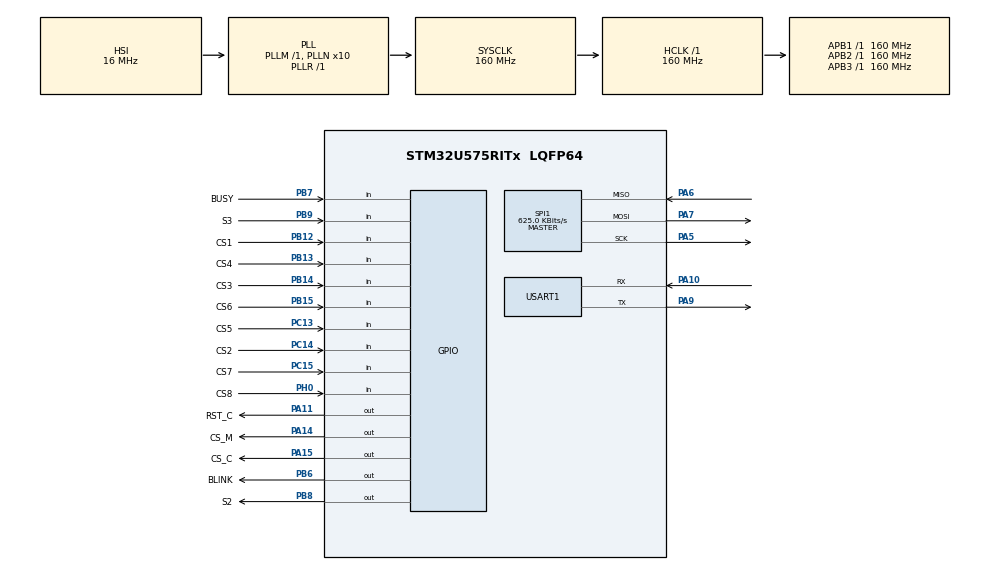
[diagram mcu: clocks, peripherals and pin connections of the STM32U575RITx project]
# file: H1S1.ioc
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CORTEX_M33_NS.userName=CORTEX_M33
Mcu.Family=STM32U5
Mcu.Name=STM32U575RITx
Mcu.Package=LQFP64
NVIC.PriorityGroup=NVIC_PRIORITYGROUP_4
NVIC.USART1_IRQn=true\:0\:0\:false\:false\:true\:true\:true\:true
PA10.Mode=Asynchronous
PA10.Signal=USART1_RX
PA11.GPIO_Label=RST_C
PA11.PinState=GPIO_PIN_RESET
PA11.Signal=GPIO_Output
PA14\ (JTCK/SWCLK).GPIO_Label=CS_M
PA14\ (JTCK/SWCLK).PinState=GPIO_PIN_SET
PA14\ (JTCK/SWCLK).Signal=GPIO_Output
PA15\ (JTDI).GPIO_Label=CS_C
PA15\ (JTDI).PinState=GPIO_PIN_SET
PA15\ (JTDI).Signal=GPIO_Output
PA5.Mode=Full_Duplex_Master
PA5.Signal=SPI1_SCK
PA6.Mode=Full_Duplex_Master
PA6.Signal=SPI1_MISO
PA7.Mode=Full_Duplex_Master
PA7.Signal=SPI1_MOSI
PA9.GPIO_ModeDefaultPP=GPIO_MODE_AF_OD
PA9.GPIO_PuPd=GPIO_PULLUP
PA9.Mode=Asynchronous
PA9.Signal=USART1_TX
PB12.GPIO_Label=CS1
PB12.Signal=GPIO_Input
PB13.GPIO_Label=CS4
PB13.Signal=GPIO_Input
PB14.GPIO_Label=CS3
PB14.Signal=GPIO_Input
PB15.GPIO_Label=CS6
PB15.Signal=GPIO_Input
PB6.GPIO_Label=BLINK
PB6.PinState=GPIO_PIN_SET
PB6.Signal=GPIO_Output
PB7.GPIO_Label=BUSY
PB7.Signal=GPIO_Input
PB8.GPIO_Label=S2
PB8.Signal=GPIO_Output
PB9.GPIO_Label=S3
PB9.Signal=GPIO_Input
PC13.GPIO_Label=CS5
PC13.Signal=GPIO_Input
PC14-OSC32_IN\ (PC14).GPIO_Label=CS2
PC14-OSC32_IN\ (PC14).Signal=GPIO_Input
PC15-OSC32_OUT\ (PC15).GPIO_Label=CS7
PC15-OSC32_OUT\ (PC15).Signal=GPIO_Input
PH0-OSC_IN\ (PH0).GPIO_Label=CS8
PH0-OSC_IN\ (PH0).Signal=GPIO_Input
ProjectManager.HeapSize=0x200
ProjectManager.StackSize=0x400
ProjectManager.TargetToolchain=STM32CubeIDE
RCC.ADCFreq_Value=16000000
RCC.AHBFreq_Value=160000000
RCC.APB1Freq_Value=160000000
RCC.APB1TimFreq_Value=160000000
RCC.APB2Freq_Value=160000000
RCC.APB2TimFreq_Value=160000000
RCC.APB3Freq_Value=160000000
RCC.CortexFreq_Value=160000000
RCC.EPOD_VALUE=16000000
RCC.HCLKFreq_Value=160000000
RCC.HSE_VALUE=16000000
RCC.HSI48_VALUE=48000000
RCC.HSI_VALUE=16000000
RCC.LSE_VALUE=32768
RCC.LSIDIV_VALUE=32000
RCC.MSI_VALUE=4000000
RCC.PLL1R=1
RCC.PLLFRACN=0
RCC.PLLN=10
RCC.PLLSourceVirtual=RCC_PLLSOURCE_HSI
RCC.SYSCLKFreq_VALUE=160000000
RCC.SYSCLKSource=RCC_SYSCLKSOURCE_PLLCLK
RCC.USBFreq_Value=48000000
RCC.VCOOutputFreq_Value=160000000
SPI1.BaudRatePrescaler=SPI_BAUDRATEPRESCALER_256
SPI1.CLKPolarity=SPI_POLARITY_LOW
SPI1.CalculateBaudRate=625.0 KBits/s
SPI1.DataSize=SPI_DATASIZE_8BIT
SPI1.Direction=SPI_DIRECTION_2LINES
SPI1.Mode=SPI_MODE_MASTER
SPI1.VirtualType=VM_MASTER
USART1.VirtualMode-Asynchronous=VM_ASYNC
VP_LPBAMQUEUE_VS_QUEUE.Mode=QUEUEMODE
VP_LPBAM_VS_SIG1.Mode=SmartRun
VP_LPBAM_VS_SIG4.Mode=LPDMA1
VP_MEMORYMAP_VS_MEMORYMAP.Mode=CurAppReg
VP_PWR_VS_SECSignals.Mode=Security/Privilege
board=custom

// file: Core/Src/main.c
/* USER CODE BEGIN Header */
/**
 ******************************************************************************
 * @file           : main.c
 * @brief          : Main program body
 ******************************************************************************
 * @attention
 *
 * Copyright (c) 2024 STMicroelectronics.
 * All rights reserved.
 *
 * This software is licensed under terms that can be found in the LICENSE file
 * in the root directory of this software component.
 * If no LICENSE file comes with this software, it is provided AS-IS.
 *
 ******************************************************************************
 */
/* USER CODE END Header */
#include "main.h"

/* USER CODE BEGIN Includes */
#include "matrix.cs"
// All common MCU c functions
//#include "C:\dropbox\_mx\_0\fw\c\matrix.c"
//#include "C:\dropbox\_mx\_0\fw\c\dsp.c"
//#include "matrix.c"
/* USER CODE END Includes */

SPI_HandleTypeDef hspi1;

UART_HandleTypeDef huart1;

void SystemClock_Config(void);
static void MX_GPIO_Init(void);
static void MX_USART1_UART_Init(void);
static void MX_SPI1_Init(void);

/* USER CODE BEGIN 0 */
char UART1_Read(void) {
	char myChar[1] = " ";
	HAL_UART_Receive(&huart1, myChar, 1, 100);
	return myChar[0];
}
/*
 void DspTx( GPIO_TypeDef *dspPort, uint16_t dspCs, int dspAddressInt, int numBytes, unsigned char bytePtr[] )
 {
 int i = 0;
 char buffer[numBytes + 3];
 buffer[0] = 0;
 buffer[1] = dspAddressInt >>8; buffer[2] = dspAddressInt & 0xff;
 for (i = 0; i < numBytes; i++)
 {
 buffer[i + 3] = bytePtr[i];
 }
 // GPIO_TypeDef *GPIOx, uint16_t GPIO_Pin, GPIO_PinState PinState
 HAL_GPIO_WritePin(dspPort, dspCs, GPIO_PIN_RESET);
 // SPI_HandleTypeDef *hspi, const uint8_t *pData, uint16_t Size, uint32_t Timeout
 HAL_SPI_Transmit(&hspi1, buffer, numBytes + 3, 1000);
 HAL_GPIO_WritePin(dspPort, dspCs, GPIO_PIN_SET);
 }
 */
/* USER CODE END 0 */

int main(void)
{

  /* MCU Configuration--------------------------------------------------------*/

  /* Reset of all peripherals, Initializes the Flash interface and the Systick. */
  HAL_Init();

  /* Configure the system clock */
  SystemClock_Config();

  /* Initialize all configured peripherals */
  MX_GPIO_Init();
  MX_USART1_UART_Init();
  MX_SPI1_Init();
  /* USER CODE BEGIN 2 */
	//HAL_GPIO_WritePin(RST_D_GPIO_Port, RST_D_Pin, GPIO_PIN_RESET);
	//HAL_Delay(10);
	//HAL_GPIO_WritePin(RST_D_GPIO_Port, RST_D_Pin, GPIO_PIN_SET);
	__HAL_UART_ENABLE_IT(&huart1, UART_IT_RXNE);
  /* USER CODE END 2 */

  /* Infinite loop */
  /* USER CODE BEGIN WHILE */
	MainInit();
	while (1) {
    /* USER CODE END WHILE */

    /* USER CODE BEGIN 3 */
		MainLoop();
	}
  /* USER CODE END 3 */
}

void SystemClock_Config(void)
{
  RCC_OscInitTypeDef RCC_OscInitStruct = {0};
  RCC_ClkInitTypeDef RCC_ClkInitStruct = {0};

  /** Configure the main internal regulator output voltage
  */
  if (HAL_PWREx_ControlVoltageScaling(PWR_REGULATOR_VOLTAGE_SCALE1) != HAL_OK)
  {
    Error_Handler();
  }

  /** Initializes the CPU, AHB and APB buses clocks
  */
  RCC_OscInitStruct.OscillatorType = RCC_OSCILLATORTYPE_HSI;
  RCC_OscInitStruct.HSIState = RCC_HSI_ON;
  RCC_OscInitStruct.HSICalibrationValue = RCC_HSICALIBRATION_DEFAULT;
  RCC_OscInitStruct.PLL.PLLState = RCC_PLL_ON;
  RCC_OscInitStruct.PLL.PLLSource = RCC_PLLSOURCE_HSI;
  RCC_OscInitStruct.PLL.PLLMBOOST = RCC_PLLMBOOST_DIV1;
  RCC_OscInitStruct.PLL.PLLM = 1;
  RCC_OscInitStruct.PLL.PLLN = 10;
  RCC_OscInitStruct.PLL.PLLP = 2;
  RCC_OscInitStruct.PLL.PLLQ = 2;
  RCC_OscInitStruct.PLL.PLLR = 1;
  RCC_OscInitStruct.PLL.PLLRGE = RCC_PLLVCIRANGE_1;
  RCC_OscInitStruct.PLL.PLLFRACN = 0;
  if (HAL_RCC_OscConfig(&RCC_OscInitStruct) != HAL_OK)
  {
    Error_Handler();
  }

  /** Initializes the CPU, AHB and APB buses clocks
  */
  RCC_ClkInitStruct.ClockType = RCC_CLOCKTYPE_HCLK|RCC_CLOCKTYPE_SYSCLK
                              |RCC_CLOCKTYPE_PCLK1|RCC_CLOCKTYPE_PCLK2
                              |RCC_CLOCKTYPE_PCLK3;
  RCC_ClkInitStruct.SYSCLKSource = RCC_SYSCLKSOURCE_PLLCLK;
  RCC_ClkInitStruct.AHBCLKDivider = RCC_SYSCLK_DIV1;
  RCC_ClkInitStruct.APB1CLKDivider = RCC_HCLK_DIV1;
  RCC_ClkInitStruct.APB2CLKDivider = RCC_HCLK_DIV1;
  RCC_ClkInitStruct.APB3CLKDivider = RCC_HCLK_DIV1;

  if (HAL_RCC_ClockConfig(&RCC_ClkInitStruct, FLASH_LATENCY_4) != HAL_OK)
  {
    Error_Handler();
  }
}

static void MX_SPI1_Init(void)
{

  SPI_AutonomousModeConfTypeDef HAL_SPI_AutonomousMode_Cfg_Struct = {0};

  /* SPI1 parameter configuration*/
  hspi1.Instance = SPI1;
  hspi1.Init.Mode = SPI_MODE_MASTER;
  hspi1.Init.Direction = SPI_DIRECTION_2LINES;
  hspi1.Init.DataSize = SPI_DATASIZE_8BIT;
  hspi1.Init.CLKPolarity = SPI_POLARITY_LOW;
  hspi1.Init.CLKPhase = SPI_PHASE_1EDGE;
  hspi1.Init.NSS = SPI_NSS_SOFT;
  hspi1.Init.BaudRatePrescaler = SPI_BAUDRATEPRESCALER_256;
  hspi1.Init.FirstBit = SPI_FIRSTBIT_MSB;
  hspi1.Init.TIMode = SPI_TIMODE_DISABLE;
  hspi1.Init.CRCCalculation = SPI_CRCCALCULATION_DISABLE;
  hspi1.Init.CRCPolynomial = 0x7;
  hspi1.Init.NSSPMode = SPI_NSS_PULSE_ENABLE;
  hspi1.Init.NSSPolarity = SPI_NSS_POLARITY_LOW;
  hspi1.Init.FifoThreshold = SPI_FIFO_THRESHOLD_01DATA;
  hspi1.Init.MasterSSIdleness = SPI_MASTER_SS_IDLENESS_00CYCLE;
  hspi1.Init.MasterInterDataIdleness = SPI_MASTER_INTERDATA_IDLENESS_00CYCLE;
  hspi1.Init.MasterReceiverAutoSusp = SPI_MASTER_RX_AUTOSUSP_DISABLE;
  hspi1.Init.MasterKeepIOState = SPI_MASTER_KEEP_IO_STATE_DISABLE;
  hspi1.Init.IOSwap = SPI_IO_SWAP_DISABLE;
  hspi1.Init.ReadyMasterManagement = SPI_RDY_MASTER_MANAGEMENT_INTERNALLY;
  hspi1.Init.ReadyPolarity = SPI_RDY_POLARITY_HIGH;
  if (HAL_SPI_Init(&hspi1) != HAL_OK)
  {
    Error_Handler();
  }
  HAL_SPI_AutonomousMode_Cfg_Struct.TriggerState = SPI_AUTO_MODE_DISABLE;
  HAL_SPI_AutonomousMode_Cfg_Struct.TriggerSelection = SPI_GRP1_GPDMA_CH0_TCF_TRG;
  HAL_SPI_AutonomousMode_Cfg_Struct.TriggerPolarity = SPI_TRIG_POLARITY_RISING;
  if (HAL_SPIEx_SetConfigAutonomousMode(&hspi1, &HAL_SPI_AutonomousMode_Cfg_Struct) != HAL_OK)
  {
    Error_Handler();
  }

}

static void MX_USART1_UART_Init(void)
{

  huart1.Instance = USART1;
  huart1.Init.BaudRate = 115200;
  huart1.Init.WordLength = UART_WORDLENGTH_8B;
  huart1.Init.StopBits = UART_STOPBITS_1;
  huart1.Init.Parity = UART_PARITY_NONE;
  huart1.Init.Mode = UART_MODE_TX_RX;
  huart1.Init.HwFlowCtl = UART_HWCONTROL_NONE;
  huart1.Init.OverSampling = UART_OVERSAMPLING_16;
  huart1.Init.OneBitSampling = UART_ONE_BIT_SAMPLE_DISABLE;
  huart1.Init.ClockPrescaler = UART_PRESCALER_DIV1;
  huart1.AdvancedInit.AdvFeatureInit = UART_ADVFEATURE_NO_INIT;
  if (HAL_UART_Init(&huart1) != HAL_OK)
  {
    Error_Handler();
  }
  if (HAL_UARTEx_SetTxFifoThreshold(&huart1, UART_TXFIFO_THRESHOLD_1_8) != HAL_OK)
  {
    Error_Handler();
  }
  if (HAL_UARTEx_SetRxFifoThreshold(&huart1, UART_RXFIFO_THRESHOLD_1_8) != HAL_OK)
  {
    Error_Handler();
  }
  if (HAL_UARTEx_DisableFifoMode(&huart1) != HAL_OK)
  {
    Error_Handler();
  }

}

static void MX_GPIO_Init(void)
{
  GPIO_InitTypeDef GPIO_InitStruct = {0};

  /* GPIO Ports Clock Enable */
  __HAL_RCC_GPIOC_CLK_ENABLE();
  __HAL_RCC_GPIOH_CLK_ENABLE();
  __HAL_RCC_GPIOA_CLK_ENABLE();
  __HAL_RCC_GPIOB_CLK_ENABLE();

  /*Configure GPIO pin Output Level */
  HAL_GPIO_WritePin(BLINK_GPIO_Port, BLINK_Pin, GPIO_PIN_SET);

  /*Configure GPIO pin Output Level */
  HAL_GPIO_WritePin(RST_C_GPIO_Port, RST_C_Pin, GPIO_PIN_RESET);

  /*Configure GPIO pin Output Level */
  HAL_GPIO_WritePin(GPIOA, CS_C_Pin, GPIO_PIN_SET);   /* CS_M (PA14) is NOT driven: released to the CM4 CS5 wire, 2026-09-14 */

  /*Configure GPIO pin Output Level */
  HAL_GPIO_WritePin(S2_GPIO_Port, S2_Pin, GPIO_PIN_RESET);

  /*Configure GPIO pins : CS5_Pin CS2_Pin CS7_Pin */
  GPIO_InitStruct.Pin = CS5_Pin|CS2_Pin|CS7_Pin;
  GPIO_InitStruct.Mode = GPIO_MODE_INPUT;
  GPIO_InitStruct.Pull = GPIO_NOPULL;
  HAL_GPIO_Init(GPIOC, &GPIO_InitStruct);

  /*Configure GPIO pin : CS8_Pin */
  GPIO_InitStruct.Pin = CS8_Pin;
  GPIO_InitStruct.Mode = GPIO_MODE_INPUT;
  GPIO_InitStruct.Pull = GPIO_NOPULL;
  HAL_GPIO_Init(CS8_GPIO_Port, &GPIO_InitStruct);

  /*Configure GPIO pins : BLINK_Pin S2_Pin */
  GPIO_InitStruct.Pin = BLINK_Pin|S2_Pin;
  GPIO_InitStruct.Mode = GPIO_MODE_OUTPUT_PP;
  GPIO_InitStruct.Pull = GPIO_NOPULL;
  GPIO_InitStruct.Speed = GPIO_SPEED_FREQ_LOW;
  HAL_GPIO_Init(GPIOB, &GPIO_InitStruct);

  /*Configure GPIO pins : RST_C_Pin CS_C_Pin (CS_M_Pin deliberately absent) */
  GPIO_InitStruct.Pin = RST_C_Pin|CS_C_Pin;
  GPIO_InitStruct.Mode = GPIO_MODE_OUTPUT_PP;
  GPIO_InitStruct.Pull = GPIO_NOPULL;
  GPIO_InitStruct.Speed = GPIO_SPEED_FREQ_LOW;
  HAL_GPIO_Init(GPIOA, &GPIO_InitStruct);

  /*Configure GPIO pin : CS_M_Pin — input, no pull, hi-Z. The 74HC595 chain latch !CS_M is
    owned by the CM4 (CS5 = GPIO27 wire to this pad, 2026-09-12); H1S1 must never drive it. */
  GPIO_InitStruct.Pin = CS_M_Pin;
  GPIO_InitStruct.Mode = GPIO_MODE_INPUT;
  GPIO_InitStruct.Pull = GPIO_NOPULL;
  HAL_GPIO_Init(CS_M_GPIO_Port, &GPIO_InitStruct);

  /*Configure GPIO pins : CS1_Pin CS4_Pin CS3_Pin CS6_Pin
                           BUSY_Pin S3_Pin */
  GPIO_InitStruct.Pin = CS1_Pin|CS4_Pin|CS3_Pin|CS6_Pin
                          |BUSY_Pin|S3_Pin;
  GPIO_InitStruct.Mode = GPIO_MODE_INPUT;
  GPIO_InitStruct.Pull = GPIO_NOPULL;
  HAL_GPIO_Init(GPIOB, &GPIO_InitStruct);

  /* USER CODE BEGIN MX_GPIO_Init_2 */
  /* ALL EIGHT CS pins (CS1-CS8) are OWNED BY THE CM4 — this MCU must never
     drive them. The CM4 masters the DSP SPI/boot bus directly; H1S1 only
     monitors. CS7 (PC15) and CS8 (PH0) additionally reach SWD_EN1 /
     SWD_EN3 through the proto wires, so an output there forces ch3
     permanently selected and breaks the CM4's SWD channel select; CS1-CS6
     driven high lost the boot-bus drive fight only by luck (2026-08-19
     bench incident, tasks.md P2). All eight are GPIO_Input in H1S1.ioc; if
     a CubeMX regen ever turns them back into outputs, that is a bug, not a
     feature. The commented-out DspTx(...CS1-CS8...) calls in
     stm32u5xx_it.c must stay commented for the same reason. */
  /* USER CODE END MX_GPIO_Init_2 */
}

void Error_Handler(void)
{
	__disable_irq();
	while (1) {
	}
}
